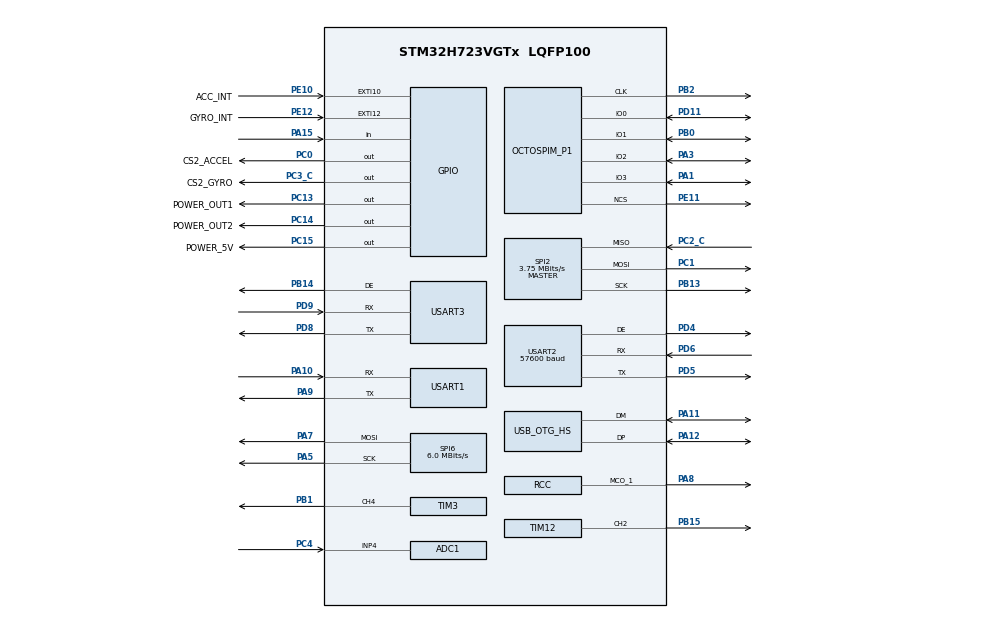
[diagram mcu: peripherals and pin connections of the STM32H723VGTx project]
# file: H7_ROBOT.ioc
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ADC1.Channel-0\#ChannelRegularConversion=ADC_CHANNEL_4
ADC1.ClockPrescaler=ADC_CLOCK_ASYNC_DIV64
ADC1.ContinuousConvMode=ENABLE
ADC1.NbrOfConversionFlag=1
ADC1.OffsetNumber-0\#ChannelRegularConversion=ADC_OFFSET_NONE
ADC1.OffsetSignedSaturation-0\#ChannelRegularConversion=DISABLE
ADC1.Rank-0\#ChannelRegularConversion=1
ADC1.SamplingTime-0\#ChannelRegularConversion=ADC_SAMPLETIME_32CYCLES_5
ADC1.master=1
CORTEX_M7.default_mode_Activation=0
Dma.ADC1.0.Direction=DMA_PERIPH_TO_MEMORY
Dma.ADC1.0.EventEnable=DISABLE
Dma.ADC1.0.FIFOMode=DMA_FIFOMODE_DISABLE
Dma.ADC1.0.Instance=DMA1_Stream0
Dma.ADC1.0.MemDataAlignment=DMA_MDATAALIGN_HALFWORD
Dma.ADC1.0.MemInc=DMA_MINC_ENABLE
Dma.ADC1.0.Mode=DMA_CIRCULAR
Dma.ADC1.0.PeriphDataAlignment=DMA_PDATAALIGN_HALFWORD
Dma.ADC1.0.PeriphInc=DMA_PINC_DISABLE
Dma.ADC1.0.Polarity=HAL_DMAMUX_REQ_GEN_RISING
Dma.ADC1.0.Priority=DMA_PRIORITY_LOW
Dma.ADC1.0.RequestNumber=1
Dma.ADC1.0.SignalID=NONE
Dma.ADC1.0.SyncEnable=DISABLE
Dma.ADC1.0.SyncPolarity=HAL_DMAMUX_SYNC_NO_EVENT
Dma.ADC1.0.SyncRequestNumber=1
Dma.ADC1.0.SyncSignalID=NONE
Dma.Request0=ADC1
Dma.Request1=USART3_RX
Dma.Request2=USART3_TX
Dma.Request3=USART1_TX
Dma.Request4=USART1_RX
Dma.Request5=USART2_RX
Dma.Request6=USART2_TX
Dma.USART1_RX.4.Direction=DMA_PERIPH_TO_MEMORY
Dma.USART1_RX.4.EventEnable=DISABLE
Dma.USART1_RX.4.FIFOMode=DMA_FIFOMODE_DISABLE
Dma.USART1_RX.4.Instance=DMA1_Stream3
Dma.USART1_RX.4.MemDataAlignment=DMA_MDATAALIGN_BYTE
Dma.USART1_RX.4.MemInc=DMA_MINC_ENABLE
Dma.USART1_RX.4.Mode=DMA_NORMAL
Dma.USART1_RX.4.PeriphDataAlignment=DMA_PDATAALIGN_BYTE
Dma.USART1_RX.4.PeriphInc=DMA_PINC_DISABLE
Dma.USART1_RX.4.Polarity=HAL_DMAMUX_REQ_GEN_RISING
Dma.USART1_RX.4.Priority=DMA_PRIORITY_LOW
Dma.USART1_RX.4.RequestNumber=1
Dma.USART1_RX.4.SignalID=NONE
Dma.USART1_RX.4.SyncEnable=DISABLE
Dma.USART1_RX.4.SyncPolarity=HAL_DMAMUX_SYNC_NO_EVENT
Dma.USART1_RX.4.SyncRequestNumber=1
Dma.USART1_RX.4.SyncSignalID=NONE
Dma.USART1_TX.3.Direction=DMA_MEMORY_TO_PERIPH
Dma.USART1_TX.3.EventEnable=DISABLE
Dma.USART1_TX.3.FIFOMode=DMA_FIFOMODE_DISABLE
Dma.USART1_TX.3.Instance=DMA1_Stream2
Dma.USART1_TX.3.MemDataAlignment=DMA_MDATAALIGN_BYTE
Dma.USART1_TX.3.MemInc=DMA_MINC_ENABLE
Dma.USART1_TX.3.Mode=DMA_NORMAL
Dma.USART1_TX.3.PeriphDataAlignment=DMA_PDATAALIGN_BYTE
Dma.USART1_TX.3.PeriphInc=DMA_PINC_DISABLE
Dma.USART1_TX.3.Polarity=HAL_DMAMUX_REQ_GEN_RISING
Dma.USART1_TX.3.Priority=DMA_PRIORITY_LOW
Dma.USART1_TX.3.RequestNumber=1
Dma.USART1_TX.3.SignalID=NONE
Dma.USART1_TX.3.SyncEnable=DISABLE
Dma.USART1_TX.3.SyncPolarity=HAL_DMAMUX_SYNC_NO_EVENT
Dma.USART1_TX.3.SyncRequestNumber=1
Dma.USART1_TX.3.SyncSignalID=NONE
Dma.USART2_RX.5.Direction=DMA_PERIPH_TO_MEMORY
Dma.USART2_RX.5.EventEnable=DISABLE
Dma.USART2_RX.5.FIFOMode=DMA_FIFOMODE_DISABLE
Dma.USART2_RX.5.Instance=DMA1_Stream4
Dma.USART2_RX.5.MemDataAlignment=DMA_MDATAALIGN_BYTE
Dma.USART2_RX.5.MemInc=DMA_MINC_ENABLE
Dma.USART2_RX.5.Mode=DMA_NORMAL
Dma.USART2_RX.5.PeriphDataAlignment=DMA_PDATAALIGN_BYTE
Dma.USART2_RX.5.PeriphInc=DMA_PINC_DISABLE
Dma.USART2_RX.5.Polarity=HAL_DMAMUX_REQ_GEN_RISING
Dma.USART2_RX.5.Priority=DMA_PRIORITY_LOW
Dma.USART2_RX.5.RequestNumber=1
Dma.USART2_RX.5.SignalID=NONE
Dma.USART2_RX.5.SyncEnable=DISABLE
Dma.USART2_RX.5.SyncPolarity=HAL_DMAMUX_SYNC_NO_EVENT
Dma.USART2_RX.5.SyncRequestNumber=1
Dma.USART2_RX.5.SyncSignalID=NONE
Dma.USART2_TX.6.Direction=DMA_MEMORY_TO_PERIPH
Dma.USART2_TX.6.EventEnable=DISABLE
Dma.USART2_TX.6.FIFOMode=DMA_FIFOMODE_DISABLE
Dma.USART2_TX.6.Instance=DMA1_Stream5
Dma.USART2_TX.6.MemDataAlignment=DMA_MDATAALIGN_BYTE
Dma.USART2_TX.6.MemInc=DMA_MINC_ENABLE
Dma.USART2_TX.6.Mode=DMA_NORMAL
Dma.USART2_TX.6.PeriphDataAlignment=DMA_PDATAALIGN_BYTE
Dma.USART2_TX.6.PeriphInc=DMA_PINC_DISABLE
Dma.USART2_TX.6.Polarity=HAL_DMAMUX_REQ_GEN_RISING
Dma.USART2_TX.6.Priority=DMA_PRIORITY_LOW
Dma.USART2_TX.6.RequestNumber=1
Dma.USART2_TX.6.SignalID=NONE
Dma.USART2_TX.6.SyncEnable=DISABLE
Dma.USART2_TX.6.SyncPolarity=HAL_DMAMUX_SYNC_NO_EVENT
Dma.USART2_TX.6.SyncRequestNumber=1
Dma.USART2_TX.6.SyncSignalID=NONE
Dma.USART3_RX.1.Direction=DMA_PERIPH_TO_MEMORY
Dma.USART3_RX.1.EventEnable=DISABLE
Dma.USART3_RX.1.FIFOMode=DMA_FIFOMODE_DISABLE
Dma.USART3_RX.1.Instance=DMA1_Stream6
Dma.USART3_RX.1.MemDataAlignment=DMA_MDATAALIGN_BYTE
Dma.USART3_RX.1.MemInc=DMA_MINC_ENABLE
Dma.USART3_RX.1.Mode=DMA_NORMAL
Dma.USART3_RX.1.PeriphDataAlignment=DMA_PDATAALIGN_BYTE
Dma.USART3_RX.1.PeriphInc=DMA_PINC_DISABLE
Dma.USART3_RX.1.Polarity=HAL_DMAMUX_REQ_GEN_RISING
Dma.USART3_RX.1.Priority=DMA_PRIORITY_LOW
Dma.USART3_RX.1.RequestNumber=1
Dma.USART3_RX.1.SignalID=NONE
Dma.USART3_RX.1.SyncEnable=DISABLE
Dma.USART3_RX.1.SyncPolarity=HAL_DMAMUX_SYNC_NO_EVENT
Dma.USART3_RX.1.SyncRequestNumber=1
Dma.USART3_RX.1.SyncSignalID=NONE
Dma.USART3_TX.2.Direction=DMA_MEMORY_TO_PERIPH
Dma.USART3_TX.2.EventEnable=DISABLE
Dma.USART3_TX.2.FIFOMode=DMA_FIFOMODE_DISABLE
Dma.USART3_TX.2.Instance=DMA1_Stream1
Dma.USART3_TX.2.MemDataAlignment=DMA_MDATAALIGN_BYTE
Dma.USART3_TX.2.MemInc=DMA_MINC_ENABLE
Dma.USART3_TX.2.Mode=DMA_NORMAL
Dma.USART3_TX.2.PeriphDataAlignment=DMA_PDATAALIGN_BYTE
Dma.USART3_TX.2.PeriphInc=DMA_PINC_DISABLE
Dma.USART3_TX.2.Polarity=HAL_DMAMUX_REQ_GEN_RISING
Dma.USART3_TX.2.Priority=DMA_PRIORITY_LOW
Dma.USART3_TX.2.RequestNumber=1
Dma.USART3_TX.2.SignalID=NONE
Dma.USART3_TX.2.SyncEnable=DISABLE
Dma.USART3_TX.2.SyncPolarity=HAL_DMAMUX_SYNC_NO_EVENT
Dma.USART3_TX.2.SyncRequestNumber=1
Dma.USART3_TX.2.SyncSignalID=NONE
FREERTOS.INCLUDE_vTaskDelayUntil=1
FREERTOS.Tasks01=defaultTask,0,128,StartDefaultTask,Default,NULL,Dynamic,NULL,NULL
FREERTOS.configENABLE_FPU=1
FREERTOS.configGENERATE_RUN_TIME_STATS=1
FREERTOS.configTOTAL_HEAP_SIZE=25600
FREERTOS.configUSE_COUNTING_SEMAPHORES=1
FREERTOS.configUSE_NEWLIB_REENTRANT=1
FREERTOS.configUSE_TIMERS=1
FREERTOS.configUSE_TRACE_FACILITY=1
Mcu.Family=STM32H7
Mcu.Name=STM32H723VGTx
Mcu.Package=LQFP100
NVIC.DMA1_Stream0_IRQn=true\:5\:0\:false\:false\:true\:true\:false\:true\:true
NVIC.DMA1_Stream1_IRQn=true\:5\:0\:false\:false\:true\:true\:false\:true\:true
NVIC.DMA1_Stream2_IRQn=true\:5\:0\:false\:false\:true\:true\:false\:true\:true
NVIC.DMA1_Stream3_IRQn=true\:5\:0\:false\:false\:true\:true\:false\:true\:true
NVIC.DMA1_Stream4_IRQn=true\:5\:0\:false\:false\:true\:true\:false\:true\:true
NVIC.DMA1_Stream5_IRQn=true\:5\:0\:false\:false\:true\:true\:false\:true\:true
NVIC.DMA1_Stream6_IRQn=true\:5\:0\:false\:false\:true\:true\:false\:true\:true
NVIC.OTG_HS_IRQn=true\:5\:0\:false\:false\:true\:true\:true\:true\:true
NVIC.PriorityGroup=NVIC_PRIORITYGROUP_4
NVIC.TIM23_IRQn=true\:15\:0\:false\:false\:true\:false\:false\:true\:true
NVIC.TimeBase=TIM23_IRQn
NVIC.TimeBaseIP=TIM23
NVIC.USART1_IRQn=true\:5\:0\:false\:false\:true\:true\:true\:true\:true
NVIC.USART2_IRQn=true\:5\:0\:false\:false\:true\:true\:true\:true\:true
NVIC.USART3_IRQn=true\:5\:0\:false\:false\:true\:true\:true\:true\:true
OCTOSPI2.ClockMode=HAL_OSPI_CLOCK_MODE_3
OCTOSPI2.ClockPrescaler=3
OCTOSPI2.DeviceSize=23
OCTOSPI2.DeviceType=SPI_DEVICE_FLASH
OCTOSPI2.FifoThreshold=8
OCTOSPI2.SampleShifting=HAL_OSPI_SAMPLE_SHIFTING_HALFCYCLE
PA1.Mode=OCTOSPI2_IOL_Port1L
PA1.Signal=OCTOSPIM_P1_IO3
PA10.Mode=Asynchronous
PA10.Signal=USART1_RX
PA11.Mode=Device_Only_FS
PA11.Signal=USB_OTG_HS_DM
PA12.Mode=Device_Only_FS
PA12.Signal=USB_OTG_HS_DP
PA13(JTMS/SWDIO).Mode=Serial_Wire
PA13(JTMS/SWDIO).Signal=DEBUG_JTMS-SWDIO
PA14(JTCK/SWCLK).Mode=Serial_Wire
PA14(JTCK/SWCLK).Signal=DEBUG_JTCK-SWCLK
PA15(JTDI).Signal=GPIO_Input
PA3.Mode=OCTOSPI2_IOL_Port1L
PA3.Signal=OCTOSPIM_P1_IO2
PA5.Mode=TX_Only_Simplex_Unidirect_Master
PA5.Signal=SPI6_SCK
PA7.Mode=TX_Only_Simplex_Unidirect_Master
PA7.Signal=SPI6_MOSI
PA8.Mode=Clock-out-1
PA8.Signal=RCC_MCO_1
PA9.Mode=Asynchronous
PA9.Signal=USART1_TX
PB0.Mode=OCTOSPI2_IOL_Port1L
PB0.Signal=OCTOSPIM_P1_IO1
PB1.Signal=S_TIM3_CH4
PB13.Mode=Full_Duplex_Master
PB13.Signal=SPI2_SCK
PB14.Mode=Hardware Flow Control (RS485)
PB14.Signal=USART3_DE
PB15.GPIO_ModeDefaultPP=GPIO_MODE_AF_PP
PB15.GPIO_PuPd=GPIO_NOPULL
PB15.GPIO_Speed=GPIO_SPEED_FREQ_LOW
PB15.Signal=S_TIM12_CH2
PB2.Mode=O2_P1_CLK
PB2.Signal=OCTOSPIM_P1_CLK
PC0.GPIO_Label=CS2_ACCEL
PC0.GPIO_Speed=GPIO_SPEED_FREQ_VERY_HIGH
PC0.PinState=GPIO_PIN_SET
PC0.Signal=GPIO_Output
PC1.Mode=Full_Duplex_Master
PC1.Signal=SPI2_MOSI
PC13.GPIO_Label=POWER_OUT1
PC13.PinState=GPIO_PIN_SET
PC13.Signal=GPIO_Output
PC14-OSC32_IN.GPIO_Label=POWER_OUT2
PC14-OSC32_IN.PinState=GPIO_PIN_SET
PC14-OSC32_IN.Signal=GPIO_Output
PC15-OSC32_OUT.GPIO_Label=POWER_5V
PC15-OSC32_OUT.PinState=GPIO_PIN_SET
PC15-OSC32_OUT.Signal=GPIO_Output
PC2_C.Mode=Full_Duplex_Master
PC2_C.Signal=SPI2_MISO
PC3_C.GPIO_Label=CS2_GYRO
PC3_C.GPIO_Speed=GPIO_SPEED_FREQ_VERY_HIGH
PC3_C.PinState=GPIO_PIN_SET
PC3_C.Signal=GPIO_Output
PC4.Signal=ADCx_INP4
PD11.Mode=OCTOSPI2_IOL_Port1L
PD11.Signal=OCTOSPIM_P1_IO0
PD4.Mode=Hardware Flow Control (RS485)
PD4.Signal=USART2_DE
PD5.Mode=Asynchronous
PD5.Signal=USART2_TX
PD6.Mode=Asynchronous
PD6.Signal=USART2_RX
PD8.Mode=Asynchronous
PD8.Signal=USART3_TX
PD9.Mode=Asynchronous
PD9.Signal=USART3_RX
PE10.GPIO_Label=ACC_INT
PE10.Signal=GPXTI10
PE11.Mode=OCTOSPI2_Port1_NCS
PE11.Signal=OCTOSPIM_P1_NCS
PE12.GPIO_Label=GYRO_INT
PE12.Signal=GPXTI12
PH0-OSC_IN.Mode=HSE-External-Oscillator
PH0-OSC_IN.Signal=RCC_OSC_IN
PH1-OSC_OUT.Mode=HSE-External-Oscillator
PH1-OSC_OUT.Signal=RCC_OSC_OUT
ProjectManager.HeapSize=0x2000
ProjectManager.StackSize=0x4000
ProjectManager.TargetToolchain=STM32CubeIDE
RCC.ADCFreq_Value=96000000
RCC.APB1Freq_Value=120000000
RCC.APB2Freq_Value=120000000
RCC.APB3Freq_Value=120000000
RCC.APB4Freq_Value=120000000
RCC.CortexFreq_Value=480000000
RCC.D1PPRE=RCC_APB3_DIV2
RCC.D2PPRE1=RCC_APB1_DIV2
RCC.D2PPRE2=RCC_APB2_DIV2
RCC.D3PPRE=RCC_APB4_DIV2
RCC.DIVM1=2
RCC.DIVM2=2
RCC.DIVN1=40
RCC.DIVN2=16
RCC.DIVP1=1
RCC.DIVQ1=4
RCC.HCLKFreq_Value=240000000
RCC.HPRE=RCC_HCLK_DIV2
RCC.HSE_VALUE=24000000
RCC.PLLSourceVirtual=RCC_PLLSOURCE_HSE
RCC.SPI6CLockSelection=RCC_SPI6CLKSOURCE_HSE
RCC.SYSCLKFreq_VALUE=480000000
RCC.SYSCLKSource=RCC_SYSCLKSOURCE_PLLCLK
RCC.USBCLockSelection=RCC_USBCLKSOURCE_HSI48
RCC.USBFreq_Value=48000000
SH.ADCx_INP4.0=ADC1_INP4,IN4-Single-Ended
SH.S_TIM12_CH2.0=TIM12_CH2,PWM Generation2 CH2
SH.S_TIM3_CH4.0=TIM3_CH4,PWM Generation4 CH4
SPI2.BaudRatePrescaler=SPI_BAUDRATEPRESCALER_32
SPI2.CLKPhase=SPI_PHASE_2EDGE
SPI2.CLKPolarity=SPI_POLARITY_HIGH
SPI2.CalculateBaudRate=3.75 MBits/s
SPI2.DataSize=SPI_DATASIZE_8BIT
SPI2.Direction=SPI_DIRECTION_2LINES
SPI2.Mode=SPI_MODE_MASTER
SPI2.VirtualType=VM_MASTER
SPI6.BaudRatePrescaler=SPI_BAUDRATEPRESCALER_4
SPI6.CalculateBaudRate=6.0 MBits/s
SPI6.DataSize=SPI_DATASIZE_8BIT
SPI6.Direction=SPI_DIRECTION_2LINES_TXONLY
SPI6.Mode=SPI_MODE_MASTER
SPI6.VirtualType=VM_MASTER
STMicroelectronics.X-CUBE-ALGOBUILD.1.4.0.LibraryCcDSPOoLibraryJjDSPOoLibrary=true
TIM12.Channel-PWM\ Generation2\ CH2=TIM_CHANNEL_2
TIM12.Period=256-1
TIM12.Prescaler=120-1
TIM12.Pulse-PWM\ Generation2\ CH2=128
TIM3.Channel-PWM\ Generation4\ CH4=TIM_CHANNEL_4
TIM3.Period=10000-1
TIM3.Prescaler=24-1
USART1.VirtualMode-Asynchronous=VM_ASYNC
USART2.BaudRate=57600
USART2.VirtualMode-Asynchronous=VM_ASYNC
USART2.VirtualMode-Hardware\ Flow\ Control\ (RS485)=VM_ASYNC
USART3.VirtualMode-Asynchronous=VM_ASYNC
USART3.VirtualMode-Hardware\ Flow\ Control\ (RS485)=VM_ASYNC
USB_DEVICE.CLASS_NAME_HS=CDC
USB_DEVICE.VirtualMode=Cdc
USB_DEVICE.VirtualModeHS=Cdc_HS
USB_OTG_HS.VirtualMode-Device_Only_FS=Device_Only_FS
VP_FREERTOS_VS_CMSIS_V1.Mode=CMSIS_V1
VP_MEMORYMAP_VS_MEMORYMAP.Mode=CurAppReg
VP_OCTOSPI2_VS_quad.Mode=quad_mode
VP_STMicroelectronics.X-CUBE-ALGOBUILD_VS_DSPOoLibraryJjLibrary_1.4.0_1.4.0.Mode=DSPOoLibraryJjLibrary
VP_SYS_VS_tim23.Mode=TIM23
VP_TIM12_VS_ClockSourceINT.Mode=Internal
VP_USB_DEVICE_VS_USB_DEVICE_CDC_HS.Mode=CDC_HS
board=custom

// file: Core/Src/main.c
/* USER CODE BEGIN Header */
/**
  ******************************************************************************
  * @file           : main.c
  * @brief          : Main program body
  ******************************************************************************
  * @attention
  *
  * Copyright (c) 2025 STMicroelectronics.
  * All rights reserved.
  *
  * This software is licensed under terms that can be found in the LICENSE file
  * in the root directory of this software component.
  * If no LICENSE file comes with this software, it is provided AS-IS.
  *
  ******************************************************************************
  */
/* USER CODE END Header */
#include "main.h"
#include "cmsis_os.h"
#include "adc.h"
#include "dma.h"
#include "memorymap.h"
#include "octospi.h"
#include "spi.h"
#include "tim.h"
#include "usart.h"
#include "usb_device.h"
#include "gpio.h"

/* USER CODE BEGIN Includes */
#include "string.h"
#include "bsp.h"
#include "modules.h"
#include "application.h"
/* USER CODE END Includes */

void SystemClock_Config(void);
void MX_FREERTOS_Init(void);

int main(void)
{

  /* MCU Configuration--------------------------------------------------------*/

  /* Reset of all peripherals, Initializes the Flash interface and the Systick. */
  HAL_Init();

  /* Configure the system clock */
  SystemClock_Config();

  /* Initialize all configured peripherals */
  MX_GPIO_Init();
  MX_DMA_Init();
  MX_USART1_UART_Init();
  MX_USART2_UART_Init();
  MX_USART3_UART_Init();
  MX_SPI6_Init();
  MX_TIM12_Init();
  MX_ADC1_Init();
  MX_SPI2_Init();
  MX_TIM3_Init();
  MX_OCTOSPI2_Init();
  /* USER CODE BEGIN 2 */
  bspInit();
  modules_init();
  OSTaskInit();
  app_loop_for_test();
  /* USER CODE END 2 */

  /* Call init function for freertos objects (in cmsis_os2.c) */
  MX_FREERTOS_Init();

  /* Start scheduler */
  osKernelStart();

  /* We should never get here as control is now taken by the scheduler */

  /* Infinite loop */
  while (1)
  {

  }
}

void SystemClock_Config(void)
{
  RCC_OscInitTypeDef RCC_OscInitStruct = {0};
  RCC_ClkInitTypeDef RCC_ClkInitStruct = {0};

  /** Supply configuration update enable
  */
  HAL_PWREx_ConfigSupply(PWR_LDO_SUPPLY);

  /** Configure the main internal regulator output voltage
  */
  __HAL_PWR_VOLTAGESCALING_CONFIG(PWR_REGULATOR_VOLTAGE_SCALE0);

  while(!__HAL_PWR_GET_FLAG(PWR_FLAG_VOSRDY)) {}

  /** Initializes the RCC Oscillators according to the specified parameters
  * in the RCC_OscInitTypeDef structure.
  */
  RCC_OscInitStruct.OscillatorType = RCC_OSCILLATORTYPE_HSI48|RCC_OSCILLATORTYPE_HSI
                              |RCC_OSCILLATORTYPE_HSE;
  RCC_OscInitStruct.HSEState = RCC_HSE_ON;
  RCC_OscInitStruct.HSIState = RCC_HSI_DIV1;
  RCC_OscInitStruct.HSICalibrationValue = 64;
  RCC_OscInitStruct.HSI48State = RCC_HSI48_ON;
  RCC_OscInitStruct.PLL.PLLState = RCC_PLL_ON;
  RCC_OscInitStruct.PLL.PLLSource = RCC_PLLSOURCE_HSE;
  RCC_OscInitStruct.PLL.PLLM = 2;
  RCC_OscInitStruct.PLL.PLLN = 40;
  RCC_OscInitStruct.PLL.PLLP = 1;
  RCC_OscInitStruct.PLL.PLLQ = 4;
  RCC_OscInitStruct.PLL.PLLR = 2;
  RCC_OscInitStruct.PLL.PLLRGE = RCC_PLL1VCIRANGE_3;
  RCC_OscInitStruct.PLL.PLLVCOSEL = RCC_PLL1VCOWIDE;
  RCC_OscInitStruct.PLL.PLLFRACN = 0;
  if (HAL_RCC_OscConfig(&RCC_OscInitStruct) != HAL_OK)
  {
    Error_Handler();
  }

  /** Initializes the CPU, AHB and APB buses clocks
  */
  RCC_ClkInitStruct.ClockType = RCC_CLOCKTYPE_HCLK|RCC_CLOCKTYPE_SYSCLK
                              |RCC_CLOCKTYPE_PCLK1|RCC_CLOCKTYPE_PCLK2
                              |RCC_CLOCKTYPE_D3PCLK1|RCC_CLOCKTYPE_D1PCLK1;
  RCC_ClkInitStruct.SYSCLKSource = RCC_SYSCLKSOURCE_PLLCLK;
  RCC_ClkInitStruct.SYSCLKDivider = RCC_SYSCLK_DIV1;
  RCC_ClkInitStruct.AHBCLKDivider = RCC_HCLK_DIV2;
  RCC_ClkInitStruct.APB3CLKDivider = RCC_APB3_DIV2;
  RCC_ClkInitStruct.APB1CLKDivider = RCC_APB1_DIV2;
  RCC_ClkInitStruct.APB2CLKDivider = RCC_APB2_DIV2;
  RCC_ClkInitStruct.APB4CLKDivider = RCC_APB4_DIV2;

  if (HAL_RCC_ClockConfig(&RCC_ClkInitStruct, FLASH_LATENCY_3) != HAL_OK)
  {
    Error_Handler();
  }
  HAL_RCC_MCOConfig(RCC_MCO1, RCC_MCO1SOURCE_HSI, RCC_MCODIV_1);
}

void HAL_TIM_PeriodElapsedCallback(TIM_HandleTypeDef *htim)
{
  if (htim->Instance == TIM23) {
    HAL_IncTick();
  }
}

void Error_Handler(void)
{
  __disable_irq();
  while (1)
  {
  }
}
